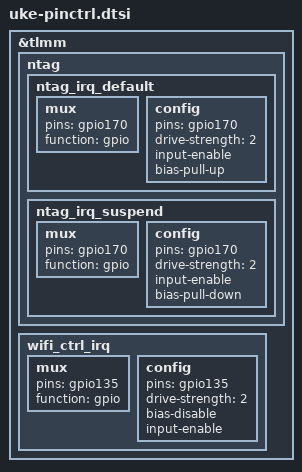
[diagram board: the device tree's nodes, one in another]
/*for PM7550BA_ADC5_GEN3_AMUX_THM4_USB_THERM_100K_PU pinctrl */
&tlmm {
		ntag {
			ntag_irq_default: ntag_irq_default {
					mux {
						pins = "gpio170";
						function = "gpio";
					};

					config {
						pins = "gpio170";
						drive-strength = <2>; /* 2 MA */
						input-enable;
						bias-pull-up;
					};
			};

			ntag_irq_suspend: ntag_irq_suspend {
					mux {
						pins = "gpio170";
						function = "gpio";
					};

					config {
						pins = "gpio170";
						drive-strength = <2>; /* 2 MA */
						input-enable;
						bias-pull-down;
					};
			};
	        }; //ntag

        wifi_ctrl_irq: wifi_ctrl_irq {
                mux {
                        pins = "gpio135";
                        function = "gpio";
                };

                config {
                        pins = "gpio135";
                        drive-strength = <2>;   /* 2 mA */
                        bias-disable;
                        input-enable;
                };
        }; //wifi
}; //tlmm
